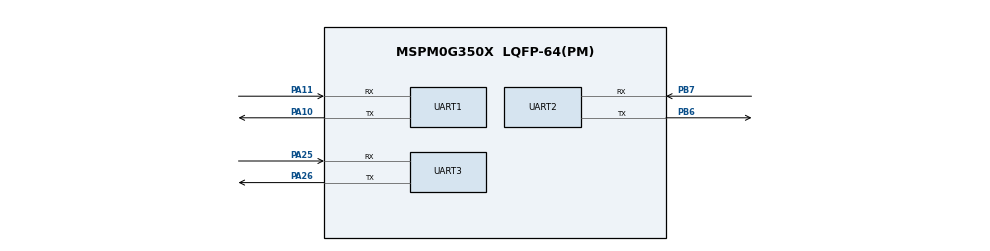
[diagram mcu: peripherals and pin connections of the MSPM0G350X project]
/**
 * @cliArgs --device "MSPM0G350X" --part "Default" --package "LQFP-64(PM)" --product "mspm0_sdk@2.02.00.05"
 * @versions {"tool":"1.21.1+3772"}
 */

/**
 * Import the modules used in this configuration.
 */
const SPI     = scripting.addModule("/ti/driverlib/SPI", {}, false);
const SPI1    = SPI.addInstance();
const SYSCTL  = scripting.addModule("/ti/driverlib/SYSCTL");
const SYSTICK = scripting.addModule("/ti/driverlib/SYSTICK");
const UART    = scripting.addModule("/ti/driverlib/UART", {}, false);
const UART1   = UART.addInstance();
const UART2   = UART.addInstance();
const UART3   = UART.addInstance();

/**
 * Write custom configuration values to the imported modules.
 */
const divider9       = system.clockTree["UDIV"];
divider9.divideValue = 2;

const gate7  = system.clockTree["MFCLKGATE"];
gate7.enable = true;

const multiplier2         = system.clockTree["PLL_QDIV"];
multiplier2.multiplyValue = 5;

const mux4       = system.clockTree["EXHFMUX"];
mux4.inputSelect = "EXHFMUX_XTAL";

const mux8       = system.clockTree["HSCLKMUX"];
mux8.inputSelect = "HSCLKMUX_SYSPLL0";

const pinFunction4       = system.clockTree["HFXT"];
pinFunction4.enable      = true;
pinFunction4.inputFreq   = 40;
pinFunction4.HFXTStartup = 10;

SPI1.$name               = "SPI_0";
SPI1.direction           = "PICO";
SPI1.peripheral.$assign  = "SPI1";
SPI1.sclkPinConfig.$name = "ti_driverlib_gpio_GPIOPinGeneric6";
SPI1.mosiPinConfig.$name = "ti_driverlib_gpio_GPIOPinGeneric7";
SPI1.cs0PinConfig.$name  = "ti_driverlib_gpio_GPIOPinGeneric9";

const Board = scripting.addModule("/ti/driverlib/Board", {}, false);

SYSCTL.forceDefaultClkConfig = true;
SYSCTL.clockTreeEn           = true;

SYSTICK.periodEnable  = true;
SYSTICK.systickEnable = true;
SYSTICK.period        = 80;

UART1.$name                    = "UART_0";
UART1.uartClkSrc               = "MFCLK";
UART1.enabledInterrupts        = ["RX"];
UART1.targetBaudRate           = 115200;
UART1.peripheral.rxPin.$assign = "PA11";
UART1.peripheral.txPin.$assign = "PA10";
UART1.txPinConfig.$name        = "ti_driverlib_gpio_GPIOPinGeneric0";
UART1.rxPinConfig.$name        = "ti_driverlib_gpio_GPIOPinGeneric1";

UART2.$name                             = "UART_1";
UART2.uartClkSrc                        = "MFCLK";
UART2.targetBaudRate                    = 115200;
UART2.enableFIFO                        = true;
UART2.rxFifoThreshold                   = "DL_UART_RX_FIFO_LEVEL_ONE_ENTRY";
UART2.txFifoThreshold                   = "DL_UART_TX_FIFO_LEVEL_3_4_EMPTY";
UART2.enabledDMATXTriggers              = "DL_UART_DMA_INTERRUPT_TX";
UART2.enabledInterrupts                 = ["DMA_DONE_RX","DMA_DONE_TX","EOT_DONE"];
UART2.peripheral.rxPin.$assign          = "PB7";
UART2.peripheral.txPin.$assign          = "PB6";
UART2.txPinConfig.$name                 = "ti_driverlib_gpio_GPIOPinGeneric4";
UART2.rxPinConfig.$name                 = "ti_driverlib_gpio_GPIOPinGeneric5";
UART2.DMA_CHANNEL_TX.$name              = "DMA_CH0";
UART2.DMA_CHANNEL_TX.addressMode        = "b2f";
UART2.DMA_CHANNEL_TX.srcLength          = "BYTE";
UART2.DMA_CHANNEL_TX.dstLength          = "BYTE";
UART2.DMA_CHANNEL_TX.peripheral.$assign = "DMA_CH0";

UART3.targetBaudRate                   = 115200;
UART3.enabledInterrupts                = ["RX"];
UART3.$name                            = "UART_3";
UART3.peripheral.$assign               = "UART3";
UART3.peripheral.rxPin.$assign         = "PA25";
UART3.peripheral.txPin.$assign         = "PA26";
UART3.txPinConfig.direction            = scripting.forceWrite("OUTPUT");
UART3.txPinConfig.hideOutputInversion  = scripting.forceWrite(false);
UART3.txPinConfig.onlyInternalResistor = scripting.forceWrite(false);
UART3.txPinConfig.passedPeripheralType = scripting.forceWrite("Digital");
UART3.txPinConfig.$name                = "ti_driverlib_gpio_GPIOPinGeneric2";
UART3.rxPinConfig.hideOutputInversion  = scripting.forceWrite(false);
UART3.rxPinConfig.onlyInternalResistor = scripting.forceWrite(false);
UART3.rxPinConfig.passedPeripheralType = scripting.forceWrite("Digital");
UART3.rxPinConfig.$name                = "ti_driverlib_gpio_GPIOPinGeneric3";

/**
 * Pinmux solution for unlocked pins/peripherals. This ensures that minor changes to the automatic solver in a future
 * version of the tool will not impact the pinmux you originally saw.  These lines can be completely deleted in order to
 * re-solve from scratch.
 */
pinFunction4.peripheral.$suggestSolution           = "SYSCTL";
pinFunction4.peripheral.hfxInPin.$suggestSolution  = "PA5";
pinFunction4.peripheral.hfxOutPin.$suggestSolution = "PA6";
SPI1.peripheral.sclkPin.$suggestSolution           = "PA17";
SPI1.peripheral.mosiPin.$suggestSolution           = "PA18";
SPI1.peripheral.cs0Pin.$suggestSolution            = "PA2";
Board.peripheral.$suggestSolution                  = "DEBUGSS";
Board.peripheral.swclkPin.$suggestSolution         = "PA20";
Board.peripheral.swdioPin.$suggestSolution         = "PA19";
UART1.peripheral.$suggestSolution                  = "UART0";
UART2.peripheral.$suggestSolution                  = "UART1";
